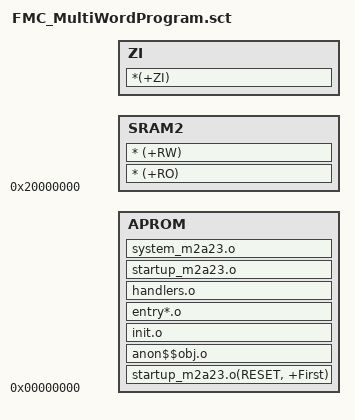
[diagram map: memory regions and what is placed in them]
LOAD_ROM 0x0
{
    APROM 0x0 
    {        
        startup_m2a23.o(RESET, +First)
        anon$$obj.o
        init.o
        entry*.o
        handlers.o
        startup_m2a23.o
        system_m2a23.o
    }

    SRAM2 0x20000000
    {
        * (+RO)	
        * (+RW)
    }

	ZI +0
	{
		*(+ZI)
	}
}

